VERSION ""

NS_ :

BS_:
BU_: TER_PEDAL ECU_CMDS TER_F_AXLE TER_IMU
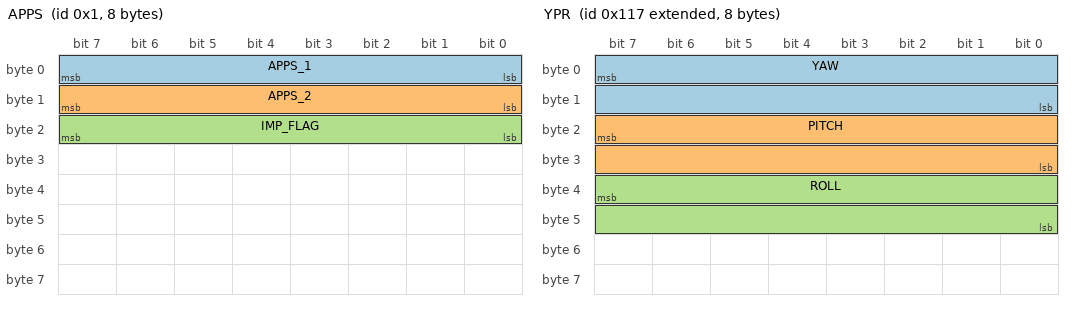
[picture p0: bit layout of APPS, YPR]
BO_ 1 APPS: 8 TER_PEDAL
   SG_ APPS_1 : 7|8@0+ (1,0) [0|255] "" Vector__XXX
   SG_ APPS_2 : 15|8@0+ (1,0) [0|255] "" Vector__XXX
   SG_ IMP_FLAG : 23|8@0+ (1,0) [0|255] "" Vector__XXX

BO_ 4 PEDAL_CMD: 8 ECU_CMDS
   SG_ CMD : 7|8@0+ (1,0) [0|1] "" Vector__XXX
   SG_ ARGS : 15|56@0+ (1,0) [0|1] "" Vector__XXX

BO_ 2 BPPS: 1 TER_PEDAL
   SG_ BPPS : 7|8@0+ (1,0) [0|1] "" Vector__XXX

BO_ 5 STEER: 8 TER_PEDAL
   SG_ ANGLE : 7|16@0- (1,0) [-360|360] "Grad" Vector__XXX

BO_ 277 rWheel: 8 TER_F_AXLE
   SG_ RPM : 7|16@0+ (1,0) [0|1] "" Vector__XXX

BO_ 278 lWheel: 8 TER_F_AXLE
   SG_ RPM : 7|16@0+ (1,0) [0|1] "" Vector__XXX

BO_ 2147483927 YPR: 8 TER_IMU
   SG_ YAW : 7|16@0+ (0.01,0) [0|1] "" Vector__XXX
   SG_ PITCH : 23|16@0+ (0.01,0) [0|1] "" Vector__XXX
   SG_ ROLL : 39|16@0+ (0.01,0) [0|1] "" Vector__XXX

CM_ BO_ 2147483927 "Signals for Yaw,Pitch,Roll in fixed Point";
BA_DEF_ BO_ "GenMsgBackgroundColor" STRING ;
BA_DEF_ BO_ "GenMsgForegroundColor" STRING ;
BA_DEF_DEF_ "GenMsgBackgroundColor" "#ffffff";
BA_DEF_DEF_ "GenMsgForegroundColor" "#000000";
